# MIMXRT1024 register map
Vendor: nxp.com; File version: 1.0
CPU: CM7 r0p1, little endian, MPU, FPU, VTOR, 4 interrupt priority bits
Registers are 32-bit, read-write, reset 0x0 unless marked. A register's access mark holds for its fields unless they carry their own. Offsets are from the block's base; [hi:lo] are bit positions; {n}, {i} and the like mark numbered series; 'fields as' and 'values as' point back to an identical list.

## TEMPMON — Temperature Monitor
Base 0x400D8000; register names take the prefix TEMPMON_; alternate view of CCM_ANALOG
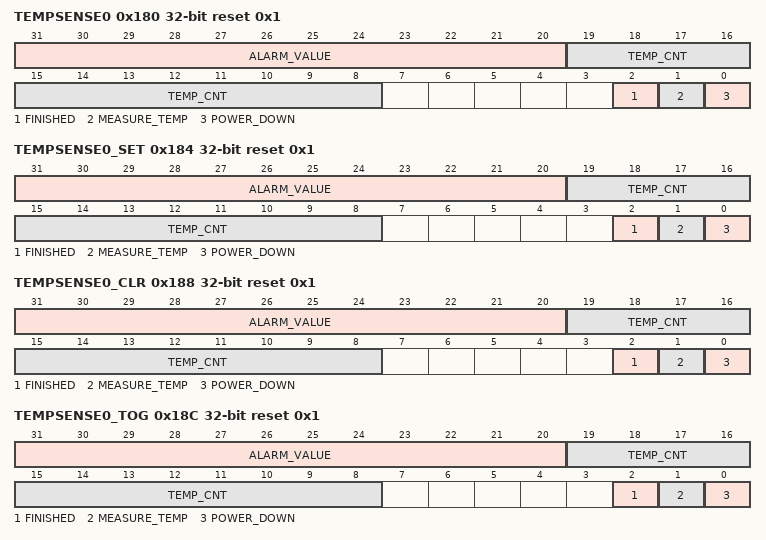
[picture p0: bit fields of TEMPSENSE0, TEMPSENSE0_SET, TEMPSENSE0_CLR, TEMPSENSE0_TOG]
0x180 TEMPSENSE0 reset 0x1 — Tempsensor Control Register 0
  [31:20] ALARM_VALUE — This bit field contains the temperature count (raw sensor output) that will generate a high alarm when TEMP_CNT is smaller than this field
  [19:8] TEMP_CNT ro — This bit field contains the last measured temperature count.
  [2] FINISHED ro — Indicates that the latest temp is valid
    0=INVALID (Last measurement is not ready yet.); 1=VALID (Last measurement is valid.)
  [1] MEASURE_TEMP — Starts the measurement process
    0=STOP (Do not start the measurement process.); 1=START (Start the measurement process.)
  [0] POWER_DOWN — This bit powers down the temperature sensor.
    0=POWER_UP (Enable power to the temperature sensor.); 1=POWER_DOWN (Power down the temperature sensor.)
0x184 TEMPSENSE0_SET reset 0x1 — Tempsensor Control Register 0
  fields as TEMPSENSE0
0x188 TEMPSENSE0_CLR reset 0x1 — Tempsensor Control Register 0
  fields as TEMPSENSE0
0x18C TEMPSENSE0_TOG reset 0x1 — Tempsensor Control Register 0
  fields as TEMPSENSE0
0x190 TEMPSENSE1 reset 0x1 — Tempsensor Control Register 1
  [15:0] MEASURE_FREQ — This bits determines how many RTC clocks to wait before automatically repeating a temperature measurement
    0=Defines a single measurement with no repeat; 1=Updates the temperature value at a RTC clock rate; 2=Updates the temperature value at a RTC/2 clock rate; 0xFFFF=Determines a two second sample period with a 32.768KHz RTC clock. Exact timings depend on the accuracy of the RTC clock.
0x194 TEMPSENSE1_SET reset 0x1 — Tempsensor Control Register 1
  fields as TEMPSENSE1
0x198 TEMPSENSE1_CLR reset 0x1 — Tempsensor Control Register 1
  fields as TEMPSENSE1
0x19C TEMPSENSE1_TOG reset 0x1 — Tempsensor Control Register 1
  fields as TEMPSENSE1
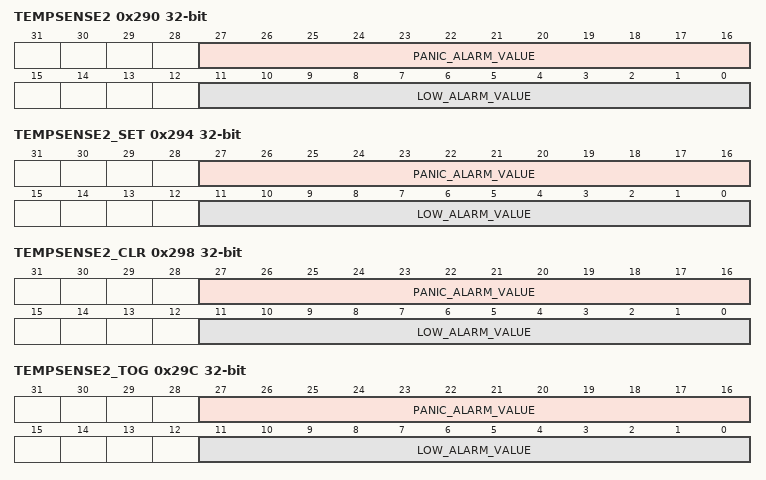
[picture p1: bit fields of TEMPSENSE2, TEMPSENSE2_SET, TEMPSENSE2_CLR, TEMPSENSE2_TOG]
0x290 TEMPSENSE2 — Tempsensor Control Register 2
  [27:16] PANIC_ALARM_VALUE — This bit field contains the temperature count that will generate a panic interrupt when TEMP_CNT is smaller than this field
  [11:0] LOW_ALARM_VALUE — This bit field contains the temperature count that will generate a low alarm interrupt when the field is exceeded by TEMP_CNT
0x294 TEMPSENSE2_SET — Tempsensor Control Register 2
  fields as TEMPSENSE2
0x298 TEMPSENSE2_CLR — Tempsensor Control Register 2
  fields as TEMPSENSE2
0x29C TEMPSENSE2_TOG — Tempsensor Control Register 2
  fields as TEMPSENSE2

## DMAMUX
Base 0x400EC000
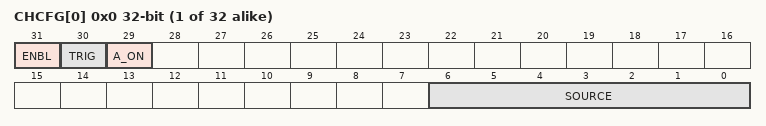
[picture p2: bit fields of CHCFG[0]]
{0x0+4i} CHCFG[{i}] (i=0..31) — Channel index Configuration Register
  [31] ENBL — DMA Mux Channel Enable
    0=DMA Mux channel is disabled; 1=DMA Mux channel is enabled
  [30] TRIG — DMA Channel Trigger Enable
    0=Triggering is disabled. If triggering is disabled and ENBL is set, the DMA Channel will simply route the specified source to the DMA channel. (Normal mode); 1=Triggering is enabled. If triggering is enabled and ENBL is set, the DMA_CH_MUX is in Periodic Trigger mode.
  [29] A_ON — DMA Channel Always Enable
    0=DMA Channel Always ON function is disabled; 1=DMA Channel Always ON function is enabled
  [6:0] SOURCE — DMA Channel Source (Slot Number)

## GPC
Base 0x400F4000; register names take the prefix GPC_
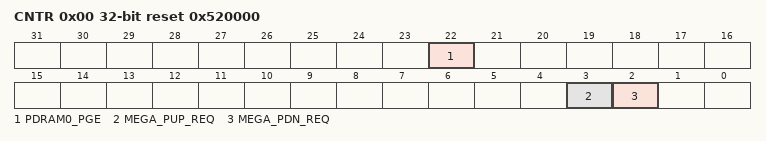
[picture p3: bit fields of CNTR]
0x00 CNTR reset 0x520000 — GPC Interface control register
  [22] PDRAM0_PGE — FlexRAM PDRAM0 Power Gate Enable
    0=FlexRAM PDRAM0 domain will keep power even if the CPU core is powered down; 1=FlexRAM PDRAM0 domain will be powered down when the CPU core is powered down
  [3] MEGA_PUP_REQ — MEGA domain (FlexRAM PDRAM1) power up request
    0=No Request; 1=Request power up sequence
  [2] MEGA_PDN_REQ — MEGA domain (FlexRAM PDRAM1) power down request
    0=No Request; 1=Request power down sequence
{0x4+4i} IMR{i} (i=1..4) — IRQ masking register {i}
  [31:0] IMR{i} — IRQ[{32i-1}:{32i-32}] masking bits: 1-irq masked, 0-irq is not masked
{0x14+4i} ISR{i} ro (i=1..4) — IRQ status resister {i}
  [31:0] ISR{i} — IRQ[{32i-1}:{32i-32}] status, read only
0x34 IMR5 — IRQ masking register 5
  [31:0] IMR5 — IRQ[159:128] masking bits: 1-irq masked, 0-irq is not masked
0x38 ISR5 ro — IRQ status resister 5
  [31:0] ISR5 — IRQ[159:128] status, read only
